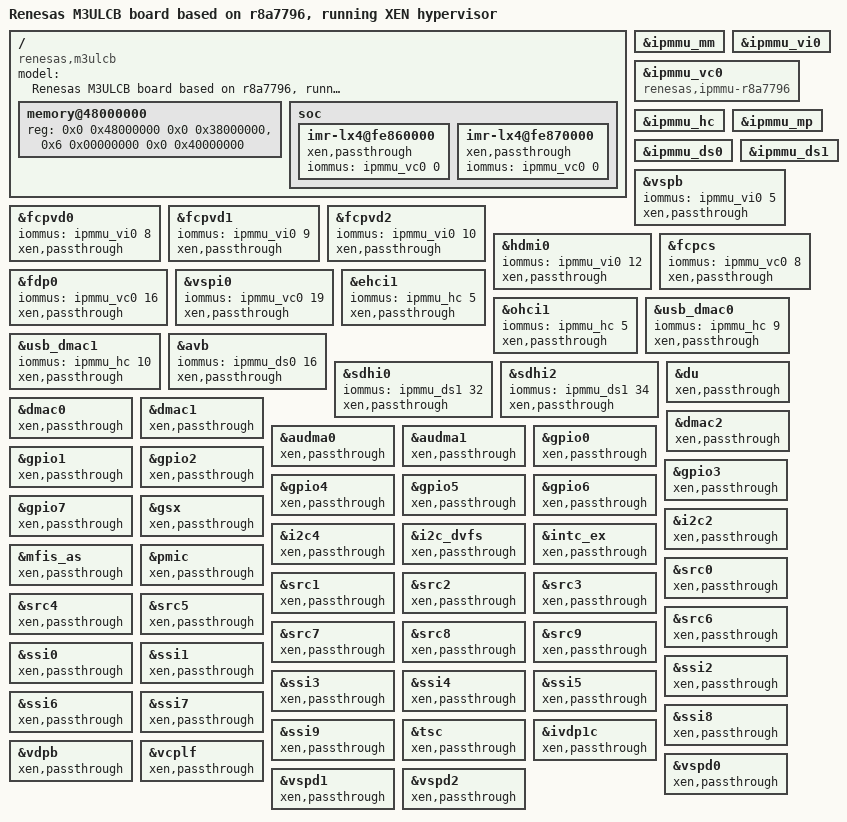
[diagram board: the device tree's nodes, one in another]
/*
 * Device Tree Source for the M3ULCB (R-Car Starter Kit Pro) board
 * running XEN hypervisor
 *
 * Copyright (C) 2016-2018 Renesas Electronics Corp.
 * Copyright (C) 2016 Cogent Embedded, Inc.
 *
 * This file is licensed under the terms of the GNU General Public License
 * version 2.  This program is licensed "as is" without any warranty of any
 * kind, whether express or implied.
 */

#include "r8a7796-m3ulcb.dts"
#include "xen-chosen.dtsi"

/ {
	model = "Renesas M3ULCB board based on r8a7796, running XEN hypervisor";
	compatible = "renesas,m3ulcb", "renesas,r8a7796";

	memory@48000000 {
		device_type = "memory";
		/* first 128MB is reserved for secure area. */
		reg = <0x0 0x48000000 0x0 0x38000000>,
		      <0x6 0x00000000 0x0 0x40000000>;
	};

	/delete-node/memory@600000000;
	/delete-node/reserved-memory;
	/delete-node/mmngr;
	/delete-node/mmngrbuf;

	/*
	 * When creating DT for the guest domain Xen inserts only dummy CPU nodes.
	 * And the number of these inserted CPU nodes is equal to the number of
	 * vCPUs assigned to this domain. All CPU properties which original DT has,
	 * such as OPP, clock, regulator, etc are not passed to the guest’s DT.
	 *
	 * Example of guest vCPU node:
	 *
	 * cpu@0 {
	 *     device_type = "cpu";
	 *     compatible = "arm,armv8";
	 *     enable-method = "psci";
	 *     reg = <0x0>;
	 * };
	 *
	 * This results in the fact that all features expecting a57_x or a53_x
	 * CPU nodes to be present get broken. This is why we have to explicitly
	 * remove the following.
	 */
	/delete-node/thermal-zones;
	/delete-node/pmu_a57;
	/delete-node/pmu_a53;
};

/delete-node/&adsp;

/* ============================ Enabled IPMMUs ===============================*/

&ipmmu_mm {
	status = "okay";
};

&ipmmu_vi0 {
	status = "okay";
};

&ipmmu_vc0 {
	compatible = "renesas,ipmmu-r8a7796";
	status = "okay";
};

&ipmmu_hc {
	status = "okay";
};

&ipmmu_mp {
	status = "okay";
};

&ipmmu_ds0 {
	status = "okay";
};

&ipmmu_ds1 {
	status = "okay";
};

/*=========================== Bus masters linked to IPMMUS ===================*/

&vspb {
	iommus = <&ipmmu_vi0 5>;
};

&fcpvd0 {
	iommus = <&ipmmu_vi0 8>;
};

&fcpvd1 {
	iommus = <&ipmmu_vi0 9>;
};

&fcpvd2 {
	iommus = <&ipmmu_vi0 10>;
};

&hdmi0 {
	iommus = <&ipmmu_vi0 12>;
};

&fcpcs {
	iommus = <&ipmmu_vc0 8>;
};

&fdp0 {
	iommus = <&ipmmu_vc0 16>;
};

&vspi0 {
	iommus = <&ipmmu_vc0 19>;
};

/ {
	soc {
		imr-lx4@fe860000 {
			xen,passthrough;
			iommus = <&ipmmu_vc0 0>;
		};
		
		imr-lx4@fe870000 {
			xen,passthrough;
			iommus = <&ipmmu_vc0 0>;
		};
	};
};

&ehci1 {
	iommus = <&ipmmu_hc 5>;
};

&ohci1 {
	iommus = <&ipmmu_hc 5>;
};

&usb_dmac0 {
	iommus = <&ipmmu_hc 9>;
};

&usb_dmac1 {
	iommus = <&ipmmu_hc 10>;
};

&avb {
	iommus = <&ipmmu_ds0 16>;
};

&sdhi0 {
	iommus = <&ipmmu_ds1 32>;
};

&sdhi2 {
	iommus = <&ipmmu_ds1 34>;
};

/* ============================ Xen pass through section =====================*/

&du				{ xen,passthrough; };
&usb_dmac0		{ xen,passthrough; };
&usb_dmac1		{ xen,passthrough; };
&dmac0			{ xen,passthrough; };
&dmac1			{ xen,passthrough; };
&dmac2			{ xen,passthrough; };
&audma0			{ xen,passthrough; };
&audma1			{ xen,passthrough; };
&avb			{ xen,passthrough; };
&fdp0			{ xen,passthrough; };
&gpio0			{ xen,passthrough; };
&gpio1			{ xen,passthrough; };
&gpio2			{ xen,passthrough; };
&gpio3			{ xen,passthrough; };
&gpio4			{ xen,passthrough; };
&gpio5			{ xen,passthrough; };
&gpio6			{ xen,passthrough; };
&gpio7			{ xen,passthrough; };
&gsx			{ xen,passthrough; };
&hdmi0			{ xen,passthrough; };
&i2c2			{ xen,passthrough; };
&i2c4			{ xen,passthrough; };
&i2c_dvfs		{ xen,passthrough; };
&intc_ex		{ xen,passthrough; };
&mfis_as		{ xen,passthrough; };
&pmic			{ xen,passthrough; };
&sdhi0			{ xen,passthrough; };
&sdhi2			{ xen,passthrough; };
&src0			{ xen,passthrough; };
&src1			{ xen,passthrough; };
&src2			{ xen,passthrough; };
&src3			{ xen,passthrough; };
&src4			{ xen,passthrough; };
&src5			{ xen,passthrough; };
&src6			{ xen,passthrough; };
&src7			{ xen,passthrough; };
&src8			{ xen,passthrough; };
&src9			{ xen,passthrough; };
&ssi0			{ xen,passthrough; };
&ssi1			{ xen,passthrough; };
&ssi2			{ xen,passthrough; };
&ssi3			{ xen,passthrough; };
&ssi4			{ xen,passthrough; };
&ssi5			{ xen,passthrough; };
&ssi6			{ xen,passthrough; };
&ssi7			{ xen,passthrough; };
&ssi8			{ xen,passthrough; };
&ssi9			{ xen,passthrough; };
&tsc			{ xen,passthrough; };
&ohci1			{ xen,passthrough; };
&ehci1			{ xen,passthrough; };
&ivdp1c			{ xen,passthrough; };
&vdpb			{ xen,passthrough; };
&vcplf			{ xen,passthrough; };
&vspd0			{ xen,passthrough; };
&vspd1			{ xen,passthrough; };
&vspd2			{ xen,passthrough; };
&vspb			{ xen,passthrough; };
&vspi0			{ xen,passthrough; };
&fcpvd0			{ xen,passthrough; };
&fcpvd1			{ xen,passthrough; };
&fcpvd2			{ xen,passthrough; };
&fcpcs			{ xen,passthrough; };
